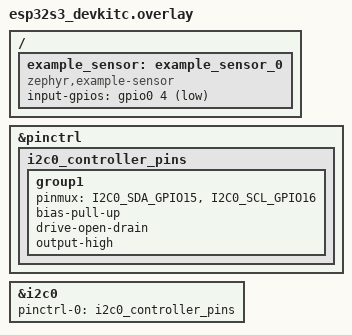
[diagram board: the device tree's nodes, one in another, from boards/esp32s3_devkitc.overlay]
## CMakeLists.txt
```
#-------------------------------------------------------------------------------
# Zephyr Example Application
#
# Copyright (c) 2021 Nordic Semiconductor ASA
# SPDX-License-Identifier: Apache-2.0

cmake_minimum_required(VERSION 3.20.0)
find_package(Zephyr REQUIRED HINTS $ENV{ZEPHYR_BASE})
project(my_zephyr_app)

project(app LANGUAGES C)

target_sources(app PRIVATE src/main.c)
```

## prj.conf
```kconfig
# Copyright (c) 2021 Nordic Semiconductor ASA
# SPDX-License-Identifier: Apache-2.0
#
# This file contains selected Kconfig options for the application.

CONFIG_SENSOR=y
CONFIG_I2C=y
CONFIG_I2C_ESP32=y
```

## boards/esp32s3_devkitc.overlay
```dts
/ {
    example_sensor: example_sensor_0 {
        compatible = "zephyr,example-sensor";
        input-gpios = <&gpio0 4 (GPIO_PULL_UP | GPIO_ACTIVE_LOW)>;
        status = "okay";
    };
};

&pinctrl {
	// custom pin settings for i2c bus 0
	i2c0_controller_pins: i2c0_controller_pins {
		group1 {
			pinmux = <I2C0_SDA_GPIO15>, <I2C0_SCL_GPIO16>; // SDA on GPIO15, SCL on GPIO16
			bias-pull-up; // enable pull-up resistors for both pins
			drive-open-drain; // required for i2c
			output-high; // start with lines high
		};
	};
};

// enable i2c
&i2c0 {
	pinctrl-0 = <&i2c0_controller_pins>;
	status = "okay";
};
```

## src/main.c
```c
#include <zephyr/kernel.h>
#include <zephyr/sys/printk.h>
#include <zephyr/device.h>
#include <zephyr/drivers/i2c.h>

#define I2C_ADDR 0x7F

int main(void)
{
	const struct device *i2c = DEVICE_DT_GET(DT_NODELABEL(i2c0));

	if(!device_is_ready(i2c)) {
		printk("i2c device not ready\n");
		return -1;
	}

	uint8_t data[] = { 0x10, 0x5, 0x8, 0x17 }; // this is just for example purposes

	int ret = i2c_write(i2c, data, sizeof(data), I2C_ADDR);

	if (ret) {
		printk("I2C write failed: %d\n", ret);
	} else {
		printk("I2C write successful\n");
	}

    printk("Complete!");

	return 0;
}
```
